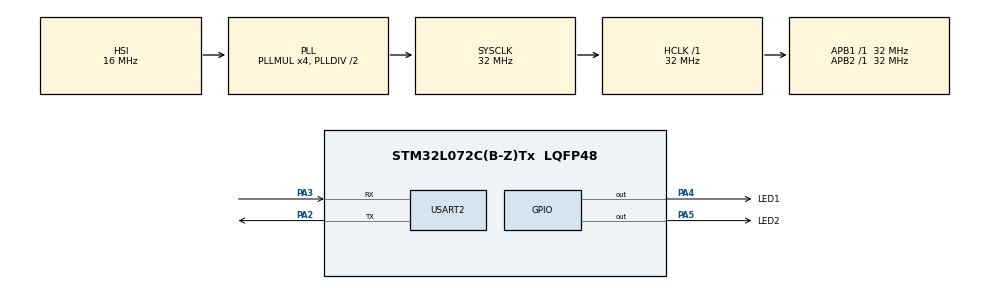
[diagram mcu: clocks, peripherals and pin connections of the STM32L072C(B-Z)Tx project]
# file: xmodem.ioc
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Mcu.Family=STM32L0
Mcu.Name=STM32L072C(B-Z)Tx
Mcu.Package=LQFP48
NVIC.USART2_IRQn=true\:0\:0\:false\:false\:true\:true\:false
PA2.Mode=Asynchronous
PA2.Signal=USART2_TX
PA3.Mode=Asynchronous
PA3.Signal=USART2_RX
PA4.GPIO_Label=LED1
PA4.Signal=GPIO_Output
PA5.GPIO_Label=LED2
PA5.Signal=GPIO_Output
ProjectManager.HeapSize=0x200
ProjectManager.StackSize=0x400
ProjectManager.TargetToolchain=MDK-ARM V5.27
RCC.AHBFreq_Value=32000000
RCC.APB1Freq_Value=32000000
RCC.APB1TimFreq_Value=32000000
RCC.APB2Freq_Value=32000000
RCC.APB2TimFreq_Value=32000000
RCC.HCLKFreq_Value=32000000
RCC.HSE_VALUE=8000000
RCC.HSI16_VALUE=16000000
RCC.HSI48_VALUE=48000000
RCC.HSI_VALUE=16000000
RCC.LSE_VALUE=32768
RCC.MSI_VALUE=2097000
RCC.PLLMUL=RCC_PLLMUL_4
RCC.SYSCLKFreq_VALUE=32000000
RCC.SYSCLKSource=RCC_SYSCLKSOURCE_PLLCLK
RCC.VCOOutputFreq_Value=64000000
USART2.VirtualMode-Asynchronous=VM_ASYNC
board=custom

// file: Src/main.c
/* USER CODE BEGIN Header */
/**
  ******************************************************************************
  * @file           : main.c
  * @brief          : Main program body
  ******************************************************************************
  * @attention
  *
  * <h2><center>&copy; Copyright (c) 2019 STMicroelectronics.
  * All rights reserved.</center></h2>
  *
  * This software component is licensed by ST under BSD 3-Clause license,
  * the "License"; You may not use this file except in compliance with the
  * License. You may obtain a copy of the License at:
  *                        opensource.org/licenses/BSD-3-Clause
  *
  ******************************************************************************
  */
/* USER CODE END Header */

#include "main.h"
#include "usart.h"
#include "gpio.h"

/* USER CODE BEGIN Includes */
#include "app_iap.h"
/* USER CODE END Includes */

void SystemClock_Config(void);

int main(void)
{
  /* USER CODE BEGIN 1 */
  //__HAL_SYSCFG_REMAPMEMORY_FLASH();
	//relocate_nvic(0x8000000);
	//__HAL_RCC_SYSCFG_CLK_ENABLE();
	__enable_irq();

  /* USER CODE END 1 */

  /* MCU Configuration--------------------------------------------------------*/

  /* Reset of all peripherals, Initializes the Flash interface and the Systick. */
  HAL_Init();

  /* Configure the system clock */
  SystemClock_Config();

  /* Initialize all configured peripherals */
  MX_GPIO_Init();
  MX_USART2_UART_Init();
  /* USER CODE BEGIN 2 */
  iap_check_memory_protection();
  if(iap_flash_get_boot_bank()==OB_BOOT_BANK2)   //boot from bank2
  {
    HAL_GPIO_WritePin(LED1_GPIO_Port,LED1_Pin,GPIO_PIN_SET);
    HAL_GPIO_WritePin(LED2_GPIO_Port,LED2_Pin,GPIO_PIN_RESET);
  }
  else
  {
    HAL_GPIO_WritePin(LED2_GPIO_Port,LED2_Pin,GPIO_PIN_SET);
    HAL_GPIO_WritePin(LED1_GPIO_Port,LED1_Pin,GPIO_PIN_RESET);
  }
	iap_start();
  /* USER CODE END 2 */

  /* Infinite loop */
  /* USER CODE BEGIN WHILE */
	HAL_Delay(2000);
  while (1)
  {
		HAL_GPIO_TogglePin(LED1_GPIO_Port,LED1_Pin);
		HAL_GPIO_TogglePin(LED2_GPIO_Port,LED2_Pin);
		HAL_Delay(500);
    /* USER CODE END WHILE */

  }
}

void SystemClock_Config(void)
{
  RCC_OscInitTypeDef RCC_OscInitStruct = {0};
  RCC_ClkInitTypeDef RCC_ClkInitStruct = {0};
  RCC_PeriphCLKInitTypeDef PeriphClkInit = {0};

  /** Configure the main internal regulator output voltage
  */
  __HAL_PWR_VOLTAGESCALING_CONFIG(PWR_REGULATOR_VOLTAGE_SCALE1);
  /** Initializes the CPU, AHB and APB busses clocks
  */
  RCC_OscInitStruct.OscillatorType = RCC_OSCILLATORTYPE_HSI;
  RCC_OscInitStruct.HSIState = RCC_HSI_ON;
  RCC_OscInitStruct.HSICalibrationValue = RCC_HSICALIBRATION_DEFAULT;
  RCC_OscInitStruct.PLL.PLLState = RCC_PLL_ON;
  RCC_OscInitStruct.PLL.PLLSource = RCC_PLLSOURCE_HSI;
  RCC_OscInitStruct.PLL.PLLMUL = RCC_PLLMUL_4;
  RCC_OscInitStruct.PLL.PLLDIV = RCC_PLLDIV_2;
  if (HAL_RCC_OscConfig(&RCC_OscInitStruct) != HAL_OK)
  {
    Error_Handler();
  }
  /** Initializes the CPU, AHB and APB busses clocks
  */
  RCC_ClkInitStruct.ClockType = RCC_CLOCKTYPE_HCLK|RCC_CLOCKTYPE_SYSCLK
                              |RCC_CLOCKTYPE_PCLK1|RCC_CLOCKTYPE_PCLK2;
  RCC_ClkInitStruct.SYSCLKSource = RCC_SYSCLKSOURCE_PLLCLK;
  RCC_ClkInitStruct.AHBCLKDivider = RCC_SYSCLK_DIV1;
  RCC_ClkInitStruct.APB1CLKDivider = RCC_HCLK_DIV1;
  RCC_ClkInitStruct.APB2CLKDivider = RCC_HCLK_DIV1;

  if (HAL_RCC_ClockConfig(&RCC_ClkInitStruct, FLASH_LATENCY_1) != HAL_OK)
  {
    Error_Handler();
  }
  PeriphClkInit.PeriphClockSelection = RCC_PERIPHCLK_USART2;
  PeriphClkInit.Usart2ClockSelection = RCC_USART2CLKSOURCE_PCLK1;
  if (HAL_RCCEx_PeriphCLKConfig(&PeriphClkInit) != HAL_OK)
  {
    Error_Handler();
  }
}

void Error_Handler(void)
{
}

/************************ (C) COPYRIGHT STMicroelectronics *****END OF FILE****/
